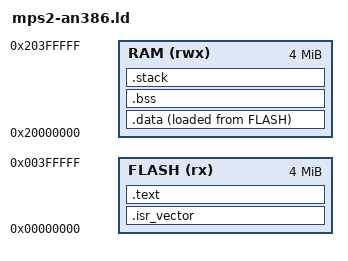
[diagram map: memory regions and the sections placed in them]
/* Linker script for ARM MPS2 FPGA Board (Cortex-M4 / mps2-an386) */
ENTRY(Reset_Handler)

MEMORY
{
    FLASH (rx)  : ORIGIN = 0x00000000, LENGTH = 4M
    RAM   (rwx) : ORIGIN = 0x20000000, LENGTH = 4M
}

SECTIONS
{
    .isr_vector :
    {
        KEEP(*(.isr_vector))
    } > FLASH

    .text :
    {
        *(.text .text.*)
        *(.rodata .rodata.*)
    } > FLASH

    _sidata = LOADADDR(.data);

    .data : ALIGN(4)
    {
        _sdata = .;
        *(.data .data.*)
        _edata = .;
    } > RAM AT > FLASH

    .bss : ALIGN(4)
    {
        _sbss = .;
        *(.bss .bss.*)
        *(COMMON)
        _ebss = .;
    } > RAM

    .stack : ALIGN(8)
    {
        . += 0x8000; /* 32 KB Stack for Cortex-M4 PQC Execution */
        _estack = .;
    } > RAM

    /DISCARD/ :
    {
        *(.comment)
        *(.note*)
    }
}
